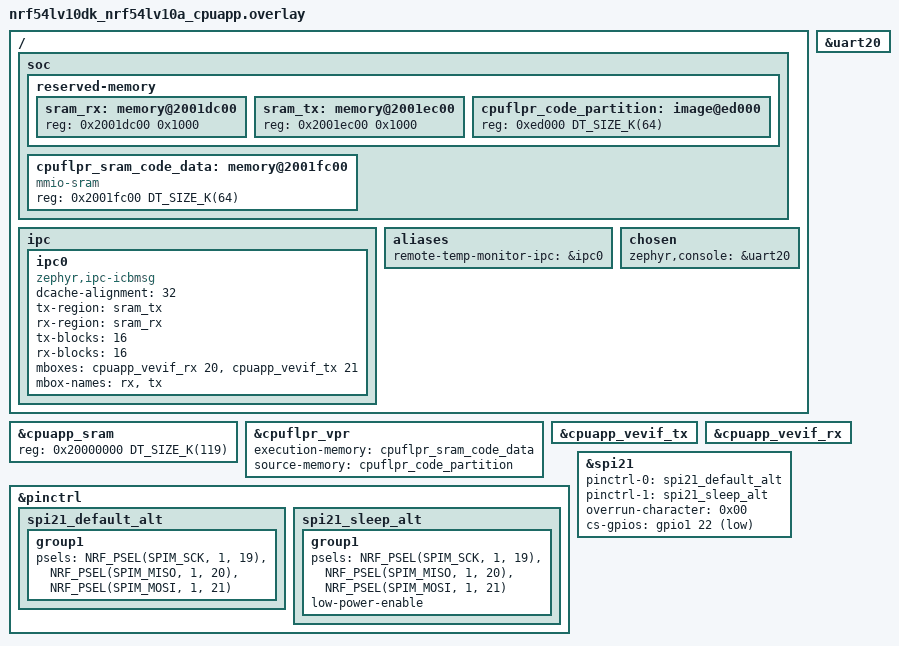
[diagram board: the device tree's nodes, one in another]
/*
 * Copyright (c) 2026 Nordic Semiconductor ASA
 *
 * SPDX-License-Identifier: LicenseRef-Nordic-5-Clause
 */

/ {
	soc {
		reserved-memory {
			#address-cells = <1>;
			#size-cells = <1>;

			sram_rx: memory@2001dc00 {
				reg = <0x2001dc00 0x1000>;
			};

			sram_tx: memory@2001ec00 {
				reg = <0x2001ec00 0x1000>;
			};

			cpuflpr_code_partition: image@ed000 {
				/* FLPR core code partition */
				reg = <0xed000 DT_SIZE_K(64)>;
			};
		};

		cpuflpr_sram_code_data: memory@2001fc00 {
			compatible = "mmio-sram";
			reg = <0x2001fc00 DT_SIZE_K(64)>;
			#address-cells = <1>;
			#size-cells = <1>;
			ranges = <0x0 0x2001fc00 DT_SIZE_K(64)>;
		};
	};

	ipc {
		ipc0: ipc0 {
			compatible = "zephyr,ipc-icbmsg";
			dcache-alignment = <32>;
			tx-region = <&sram_tx>;
			rx-region = <&sram_rx>;
			tx-blocks = <16>;
			rx-blocks = <16>;
			mboxes = <&cpuapp_vevif_rx 20>, <&cpuapp_vevif_tx 21>;
			mbox-names = "rx", "tx";
			status = "okay";
		};
	};

	aliases {
		remote-temp-monitor-ipc = &ipc0;
	};

	chosen {
		zephyr,console = &uart20;
	};
};

&uart20 {
	status = "okay";
};

&cpuapp_sram {
	reg = <0x20000000 DT_SIZE_K(119)>;
	ranges = <0x0 0x20000000 DT_SIZE_K(119)>;
};

&cpuflpr_vpr {
	status = "okay";
	execution-memory = <&cpuflpr_sram_code_data>;
	source-memory = <&cpuflpr_code_partition>;
};

&cpuapp_vevif_tx {
	status = "okay";
};

&cpuapp_vevif_rx {
	status = "okay";
};

&pinctrl {
	spi21_default_alt: spi21_default_alt {
		group1 {
			psels = <NRF_PSEL(SPIM_SCK, 1, 19)>,
				<NRF_PSEL(SPIM_MISO, 1, 20)>,
				<NRF_PSEL(SPIM_MOSI, 1, 21)>;
		};
	};

	spi21_sleep_alt: spi21_sleep_alt {
		group1 {
			psels = <NRF_PSEL(SPIM_SCK, 1, 19)>,
				<NRF_PSEL(SPIM_MISO, 1, 20)>,
				<NRF_PSEL(SPIM_MOSI, 1, 21)>;
			low-power-enable;
		};
	};
};

app_spi: &spi21 {
	status = "okay";
	pinctrl-0 = <&spi21_default_alt>;
	pinctrl-1 = <&spi21_sleep_alt>;
	pinctrl-names = "default", "sleep";
	overrun-character = <0x00>;
	cs-gpios = <&gpio1 22 GPIO_ACTIVE_LOW>;
};
